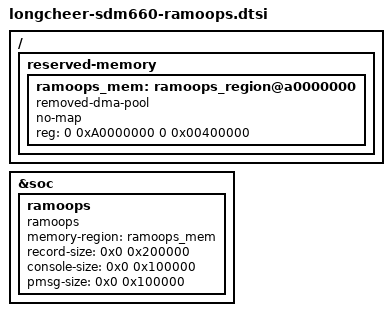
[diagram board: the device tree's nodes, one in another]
/* Copyright (c) 2019, The Linux Foundation. All rights reserved.
 *
 * This program is free software; you can redistribute it and/or modify
 * it under the terms of the GNU General Public License version 2 and
 * only version 2 as published by the Free Software Foundation.
 *
 * This program is distributed in the hope that it will be useful,
 * but WITHOUT ANY WARRANTY; without even the implied warranty of
 * MERCHANTABILITY or FITNESS FOR A PARTICULAR PURPOSE.  See the
 * GNU General Public License for more details.
 */

/* ramoops dts configuration */
/ {
	reserved-memory {
		ramoops_mem: ramoops_region@a0000000 {
			compatible = "removed-dma-pool";
			no-map;
			reg = <0 0xA0000000 0 0x00400000>;
		};
	};
};

&soc {
	ramoops {
		compatible = "ramoops";
		memory-region = <&ramoops_mem>;
		/*
		 * ramoops_parse_dt_size() reads these with
		 * of_property_read_u64(), which fails with -EOVERFLOW
		 * when the property is a single 32-bit cell.  Written as
		 * one cell they never parsed at all: ramoops_probe()
		 * failed with "failed to parse property console-size:
		 * -75" and the device had no pstore, so every panic was
		 * lost.  Keep them 64-bit.
		 *
		 * Layout over the 4 MiB region, in the order
		 * ramoops_probe() allocates it.  Dumps come first and are
		 * the one zone ramoops does not zap on probe, so a panic
		 * record survives the reset and is readable on the next
		 * boot.
		 */
		record-size = <0x0 0x200000>;
		console-size = <0x0 0x100000>;
		pmsg-size = <0x0 0x100000>;
	};
};
